# CTRL_MODULE_CORE register map
Vendor: Texas Instruments
Registers are 32-bit, access per field, reset 0x0 unless marked. A register's access mark holds for its fields unless they carry their own. Offsets are as the file gives them; [hi:lo] are bit positions; {n}, {i} and the like mark numbered series.

## CTRL_MODULE_CORE (part 4 of 5)
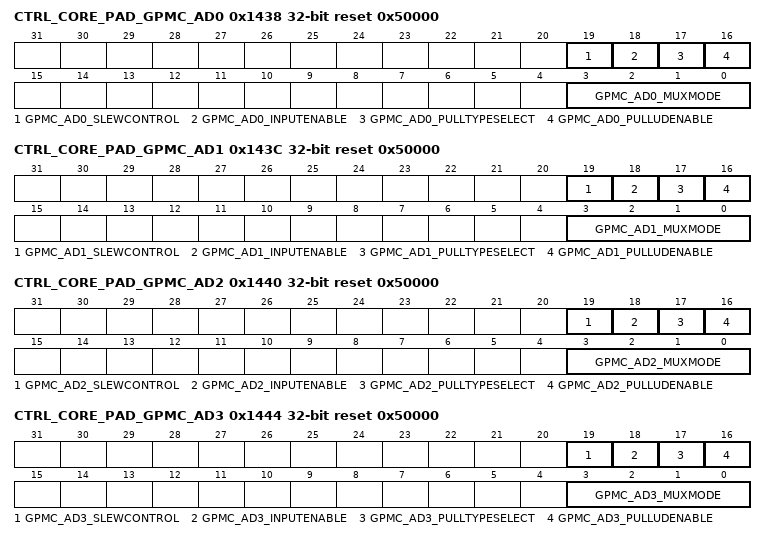
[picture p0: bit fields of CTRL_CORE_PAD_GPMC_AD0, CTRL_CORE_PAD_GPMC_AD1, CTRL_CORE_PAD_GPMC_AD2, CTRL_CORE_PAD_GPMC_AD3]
0x1438 CTRL_CORE_PAD_GPMC_AD0 reset 0x50000
  [19] GPMC_AD0_SLEWCONTROL rw
    0=Fast_slew_is_selected; 1=Slow_slew_is_selected
  [18] GPMC_AD0_INPUTENABLE rw
    0=Receive_mode_is_disabled; 1=Receive_mode_is_enabled
  [17] GPMC_AD0_PULLTYPESELECT rw
    0=Pull_Down_is_selected; 1=Pull_Up_is_selected
  [16] GPMC_AD0_PULLUDENABLE rw
    0=Enables_weak_Pull_Up/Down; 1=Disables_weak_Pull_Up/Down
  [3:0] GPMC_AD0_MUXMODE rw
    0=GPMC_AD0; 1=RGMII1_RXD2; 14=GPIO1_14; 15=SYSBOOT0
0x143C CTRL_CORE_PAD_GPMC_AD1 reset 0x50000
  [19] GPMC_AD1_SLEWCONTROL rw
    0=Fast_slew_is_selected; 1=Slow_slew_is_selected
  [18] GPMC_AD1_INPUTENABLE rw
    0=Receive_mode_is_disabled; 1=Receive_mode_is_enabled
  [17] GPMC_AD1_PULLTYPESELECT rw
    0=Pull_Down_is_selected; 1=Pull_Up_is_selected
  [16] GPMC_AD1_PULLUDENABLE rw
    0=Enables_weak_Pull_Up/Down; 1=Disables_weak_Pull_Up/Down
  [3:0] GPMC_AD1_MUXMODE rw
    0=GPMC_AD1; 1=RGMII1_RXD1; 14=GPIO1_15; 15=SYSBOOT1
0x1440 CTRL_CORE_PAD_GPMC_AD2 reset 0x50000
  [19] GPMC_AD2_SLEWCONTROL rw
    0=Fast_slew_is_selected; 1=Slow_slew_is_selected
  [18] GPMC_AD2_INPUTENABLE rw
    0=Receive_mode_is_disabled; 1=Receive_mode_is_enabled
  [17] GPMC_AD2_PULLTYPESELECT rw
    0=Pull_Down_is_selected; 1=Pull_Up_is_selected
  [16] GPMC_AD2_PULLUDENABLE rw
    0=Enables_weak_Pull_Up/Down; 1=Disables_weak_Pull_Up/Down
  [3:0] GPMC_AD2_MUXMODE rw
    0=GPMC_AD2; 1=RGMII1_RXD0; 14=GPIO1_16; 15=SYSBOOT2
0x1444 CTRL_CORE_PAD_GPMC_AD3 reset 0x50000
  [19] GPMC_AD3_SLEWCONTROL rw
    0=Fast_slew_is_selected; 1=Slow_slew_is_selected
  [18] GPMC_AD3_INPUTENABLE rw
    0=Receive_mode_is_disabled; 1=Receive_mode_is_enabled
  [17] GPMC_AD3_PULLTYPESELECT rw
    0=Pull_Down_is_selected; 1=Pull_Up_is_selected
  [16] GPMC_AD3_PULLUDENABLE rw
    0=Enables_weak_Pull_Up/Down; 1=Disables_weak_Pull_Up/Down
  [3:0] GPMC_AD3_MUXMODE rw
    0=GPMC_AD3; 1=QSPI1_RTCLK; 14=GPIO1_17; 15=SYSBOOT3
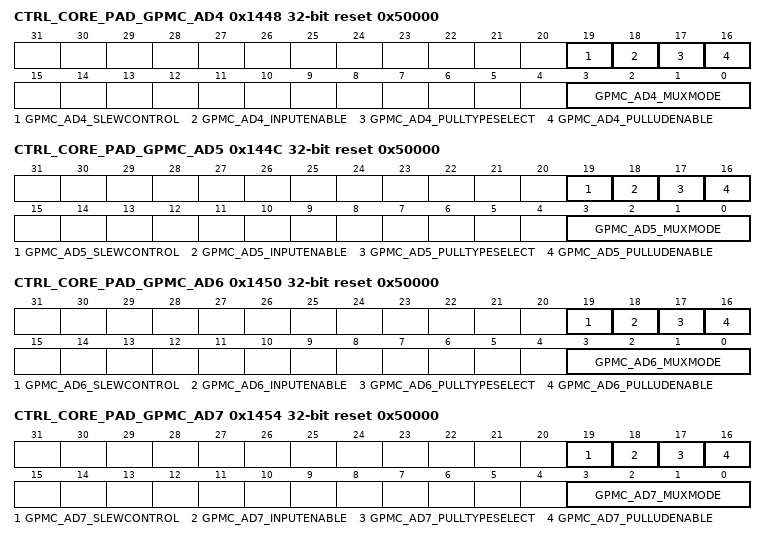
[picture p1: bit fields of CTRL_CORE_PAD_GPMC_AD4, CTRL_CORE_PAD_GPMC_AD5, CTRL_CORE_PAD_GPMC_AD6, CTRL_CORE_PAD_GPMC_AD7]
0x1448 CTRL_CORE_PAD_GPMC_AD4 reset 0x50000
  [19] GPMC_AD4_SLEWCONTROL rw
    0=Fast_slew_is_selected; 1=Slow_slew_is_selected
  [18] GPMC_AD4_INPUTENABLE rw
    0=Receive_mode_is_disabled; 1=Receive_mode_is_enabled
  [17] GPMC_AD4_PULLTYPESELECT rw
    0=Pull_Down_is_selected; 1=Pull_Up_is_selected
  [16] GPMC_AD4_PULLUDENABLE rw
    0=Enables_weak_Pull_Up/Down; 1=Disables_weak_Pull_Up/Down
  [3:0] GPMC_AD4_MUXMODE rw
    0=GPMC_AD4; 1=CAM_STROBE; 14=GPIO1_18; 15=SYSBOOT4
0x144C CTRL_CORE_PAD_GPMC_AD5 reset 0x50000
  [19] GPMC_AD5_SLEWCONTROL rw
    0=Fast_slew_is_selected; 1=Slow_slew_is_selected
  [18] GPMC_AD5_INPUTENABLE rw
    0=Receive_mode_is_disabled; 1=Receive_mode_is_enabled
  [17] GPMC_AD5_PULLTYPESELECT rw
    0=Pull_Down_is_selected; 1=Pull_Up_is_selected
  [16] GPMC_AD5_PULLUDENABLE rw
    0=Enables_weak_Pull_Up/Down; 1=Disables_weak_Pull_Up/Down
  [3:0] GPMC_AD5_MUXMODE rw
    0=GPMC_AD5; 2=UART2_TXD; 3=TIMER6; 4=SPI3_D1; 14=GPIO1_19; 15=SYSBOOT5
0x1450 CTRL_CORE_PAD_GPMC_AD6 reset 0x50000
  [19] GPMC_AD6_SLEWCONTROL rw
    0=Fast_slew_is_selected; 1=Slow_slew_is_selected
  [18] GPMC_AD6_INPUTENABLE rw
    0=Receive_mode_is_disabled; 1=Receive_mode_is_enabled
  [17] GPMC_AD6_PULLTYPESELECT rw
    0=Pull_Down_is_selected; 1=Pull_Up_is_selected
  [16] GPMC_AD6_PULLUDENABLE rw
    0=Enables_weak_Pull_Up/Down; 1=Disables_weak_Pull_Up/Down
  [3:0] GPMC_AD6_MUXMODE rw
    0=GPMC_AD6; 2=UART2_RXD; 3=TIMER5; 4=SPI3_D0; 14=GPIO1_20; 15=SYSBOOT6
0x1454 CTRL_CORE_PAD_GPMC_AD7 reset 0x50000
  [19] GPMC_AD7_SLEWCONTROL rw
    0=Fast_slew_is_selected; 1=Slow_slew_is_selected
  [18] GPMC_AD7_INPUTENABLE rw
    0=Receive_mode_is_disabled; 1=Receive_mode_is_enabled
  [17] GPMC_AD7_PULLTYPESELECT rw
    0=Pull_Down_is_selected; 1=Pull_Up_is_selected
  [16] GPMC_AD7_PULLUDENABLE rw
    0=Enables_weak_Pull_Up/Down; 1=Disables_weak_Pull_Up/Down
  [3:0] GPMC_AD7_MUXMODE rw
    0=GPMC_AD7; 1=CAM_SHUTTER; 3=TIMER4; 4=SPI3_SCLK; 14=GPIO1_21; 15=DRIVER_OFF
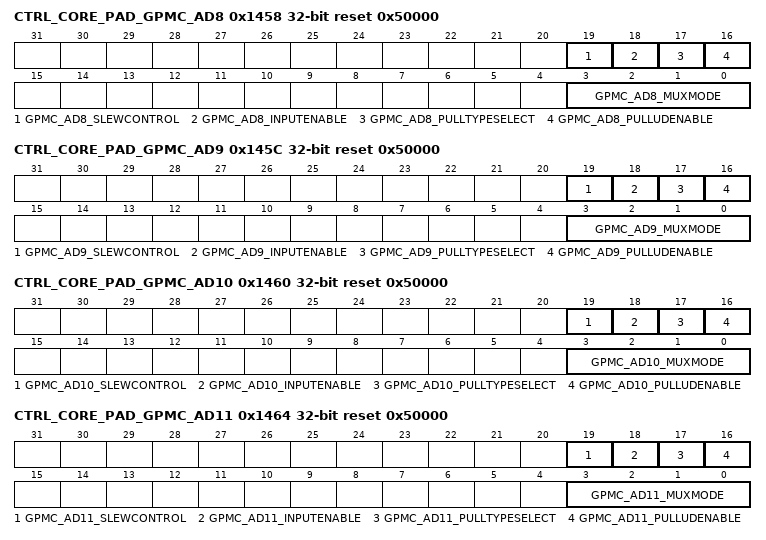
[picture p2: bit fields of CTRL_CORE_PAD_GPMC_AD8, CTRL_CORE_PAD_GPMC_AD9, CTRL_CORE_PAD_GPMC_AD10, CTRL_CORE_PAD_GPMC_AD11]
0x1458 CTRL_CORE_PAD_GPMC_AD8 reset 0x50000
  [19] GPMC_AD8_SLEWCONTROL rw
    0=Fast_slew_is_selected; 1=Slow_slew_is_selected
  [18] GPMC_AD8_INPUTENABLE rw
    0=Receive_mode_is_disabled; 1=Receive_mode_is_enabled
  [17] GPMC_AD8_PULLTYPESELECT rw
    0=Pull_Down_is_selected; 1=Pull_Up_is_selected
  [16] GPMC_AD8_PULLUDENABLE rw
    0=Enables_weak_Pull_Up/Down; 1=Disables_weak_Pull_Up/Down
  [3:0] GPMC_AD8_MUXMODE rw
    0=GPMC_AD8; 3=TIMER7; 4=SPI3_CS0; 14=GPIO1_22; 15=SYSBOOT8
0x145C CTRL_CORE_PAD_GPMC_AD9 reset 0x50000
  [19] GPMC_AD9_SLEWCONTROL rw
    0=Fast_slew_is_selected; 1=Slow_slew_is_selected
  [18] GPMC_AD9_INPUTENABLE rw
    0=Receive_mode_is_disabled; 1=Receive_mode_is_enabled
  [17] GPMC_AD9_PULLTYPESELECT rw
    0=Pull_Down_is_selected; 1=Pull_Up_is_selected
  [16] GPMC_AD9_PULLUDENABLE rw
    0=Enables_weak_Pull_Up/Down; 1=Disables_weak_Pull_Up/Down
  [3:0] GPMC_AD9_MUXMODE rw
    0=GPMC_AD9; 3=ECAP1_IN_PWM1_OUT; 4=SPI3_CS1; 14=GPIO1_23; 15=SYSBOOT9
0x1460 CTRL_CORE_PAD_GPMC_AD10 reset 0x50000
  [19] GPMC_AD10_SLEWCONTROL rw
    0=Fast_slew_is_selected; 1=Slow_slew_is_selected
  [18] GPMC_AD10_INPUTENABLE rw
    0=Receive_mode_is_disabled; 1=Receive_mode_is_enabled
  [17] GPMC_AD10_PULLTYPESELECT rw
    0=Pull_Down_is_selected; 1=Pull_Up_is_selected
  [16] GPMC_AD10_PULLUDENABLE rw
    0=Enables_weak_Pull_Up/Down; 1=Disables_weak_Pull_Up/Down
  [3:0] GPMC_AD10_MUXMODE rw
    0=GPMC_AD10; 3=TIMER2; 14=GPIO1_24; 15=SYSBOOT10
0x1464 CTRL_CORE_PAD_GPMC_AD11 reset 0x50000
  [19] GPMC_AD11_SLEWCONTROL rw
    0=Fast_slew_is_selected; 1=Slow_slew_is_selected
  [18] GPMC_AD11_INPUTENABLE rw
    0=Receive_mode_is_disabled; 1=Receive_mode_is_enabled
  [17] GPMC_AD11_PULLTYPESELECT rw
    0=Pull_Down_is_selected; 1=Pull_Up_is_selected
  [16] GPMC_AD11_PULLUDENABLE rw
    0=Enables_weak_Pull_Up/Down; 1=Disables_weak_Pull_Up/Down
  [3:0] GPMC_AD11_MUXMODE rw
    0=GPMC_AD11; 3=TIMER3; 14=GPIO1_25; 15=SYSBOOT11
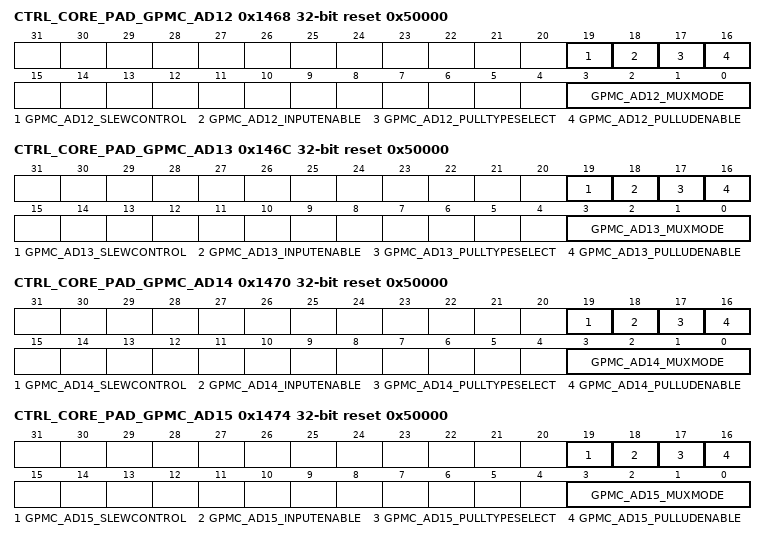
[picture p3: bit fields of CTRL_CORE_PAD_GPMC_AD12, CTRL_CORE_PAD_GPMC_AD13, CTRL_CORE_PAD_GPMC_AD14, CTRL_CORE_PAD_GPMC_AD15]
0x1468 CTRL_CORE_PAD_GPMC_AD12 reset 0x50000
  [19] GPMC_AD12_SLEWCONTROL rw
    0=Fast_slew_is_selected; 1=Slow_slew_is_selected
  [18] GPMC_AD12_INPUTENABLE rw
    0=Receive_mode_is_disabled; 1=Receive_mode_is_enabled
  [17] GPMC_AD12_PULLTYPESELECT rw
    0=Pull_Down_is_selected; 1=Pull_Up_is_selected
  [16] GPMC_AD12_PULLUDENABLE rw
    0=Enables_weak_Pull_Up/Down; 1=Disables_weak_Pull_Up/Down
  [3:0] GPMC_AD12_MUXMODE rw
    0=GPMC_AD12; 14=GPIO1_26; 15=SYSBOOT12
0x146C CTRL_CORE_PAD_GPMC_AD13 reset 0x50000
  [19] GPMC_AD13_SLEWCONTROL rw
    0=Fast_slew_is_selected; 1=Slow_slew_is_selected
  [18] GPMC_AD13_INPUTENABLE rw
    0=Receive_mode_is_disabled; 1=Receive_mode_is_enabled
  [17] GPMC_AD13_PULLTYPESELECT rw
    0=Pull_Down_is_selected; 1=Pull_Up_is_selected
  [16] GPMC_AD13_PULLUDENABLE rw
    0=Enables_weak_Pull_Up/Down; 1=Disables_weak_Pull_Up/Down
  [3:0] GPMC_AD13_MUXMODE rw
    0=GPMC_AD13; 1=RGMII1_RXC; 14=GPIO1_27; 15=SYSBOOT13
0x1470 CTRL_CORE_PAD_GPMC_AD14 reset 0x50000
  [19] GPMC_AD14_SLEWCONTROL rw
    0=Fast_slew_is_selected; 1=Slow_slew_is_selected
  [18] GPMC_AD14_INPUTENABLE rw
    0=Receive_mode_is_disabled; 1=Receive_mode_is_enabled
  [17] GPMC_AD14_PULLTYPESELECT rw
    0=Pull_Down_is_selected; 1=Pull_Up_is_selected
  [16] GPMC_AD14_PULLUDENABLE rw
    0=Enables_weak_Pull_Up/Down; 1=Disables_weak_Pull_Up/Down
  [3:0] GPMC_AD14_MUXMODE rw
    0=GPMC_AD14; 4=SPI2_CS1; 14=GPIO1_28; 15=SYSBOOT14
0x1474 CTRL_CORE_PAD_GPMC_AD15 reset 0x50000
  [19] GPMC_AD15_SLEWCONTROL rw
    0=Fast_slew_is_selected; 1=Slow_slew_is_selected
  [18] GPMC_AD15_INPUTENABLE rw
    0=Receive_mode_is_disabled; 1=Receive_mode_is_enabled
  [17] GPMC_AD15_PULLTYPESELECT rw
    0=Pull_Down_is_selected; 1=Pull_Up_is_selected
  [16] GPMC_AD15_PULLUDENABLE rw
    0=Enables_weak_Pull_Up/Down; 1=Disables_weak_Pull_Up/Down
  [3:0] GPMC_AD15_MUXMODE rw
    0=GPMC_AD15; 4=SPI2_CS0; 14=GPIO1_29; 15=SYSBOOT15
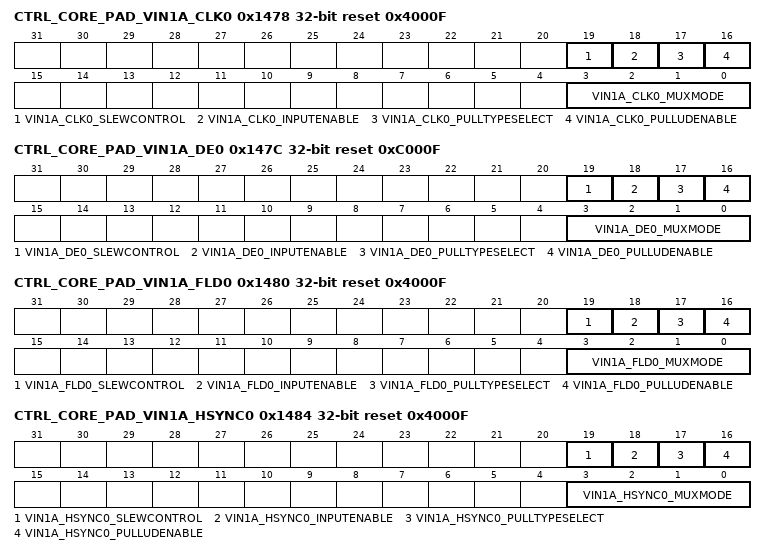
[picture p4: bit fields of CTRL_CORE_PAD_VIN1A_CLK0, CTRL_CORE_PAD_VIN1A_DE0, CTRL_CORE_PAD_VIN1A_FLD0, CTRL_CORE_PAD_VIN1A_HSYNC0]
0x1478 CTRL_CORE_PAD_VIN1A_CLK0 reset 0x4000F
  [19] VIN1A_CLK0_SLEWCONTROL rw
    0=Fast_slew_is_selected; 1=Slow_slew_is_selected
  [18] VIN1A_CLK0_INPUTENABLE rw
    0=Receive_mode_is_disabled; 1=Receive_mode_is_enabled
  [17] VIN1A_CLK0_PULLTYPESELECT rw
    0=Pull_Down_is_selected; 1=Pull_Up_is_selected
  [16] VIN1A_CLK0_PULLUDENABLE rw
    0=Enables_weak_Pull_Up/Down; 1=Disables_weak_Pull_Up/Down
  [3:0] VIN1A_CLK0_MUXMODE rw
    0=VIN1A_CLK0; 1=CPI_PCLK; 4=CLKOUT0; 14=GPIO1_30; 15=DRIVER_OFF
0x147C CTRL_CORE_PAD_VIN1A_DE0 reset 0xC000F
  [19] VIN1A_DE0_SLEWCONTROL rw
    0=Fast_slew_is_selected; 1=Slow_slew_is_selected
  [18] VIN1A_DE0_INPUTENABLE rw
    0=Receive_mode_is_disabled; 1=Receive_mode_is_enabled
  [17] VIN1A_DE0_PULLTYPESELECT rw
    0=Pull_Down_is_selected; 1=Pull_Up_is_selected
  [16] VIN1A_DE0_PULLUDENABLE rw
    0=Enables_weak_Pull_Up/Down; 1=Disables_weak_Pull_Up/Down
  [3:0] VIN1A_DE0_MUXMODE rw
    0=VIN1A_DE0; 1=CPI_HSYNC; 2=VIN1B_CLK1; 4=CLKOUT1; 14=GPIO1_31; 15=DRIVER_OFF
0x1480 CTRL_CORE_PAD_VIN1A_FLD0 reset 0x4000F
  [19] VIN1A_FLD0_SLEWCONTROL rw
    0=Fast_slew_is_selected; 1=Slow_slew_is_selected
  [18] VIN1A_FLD0_INPUTENABLE rw
    0=Receive_mode_is_disabled; 1=Receive_mode_is_enabled
  [17] VIN1A_FLD0_PULLTYPESELECT rw
    0=Pull_Down_is_selected; 1=Pull_Up_is_selected
  [16] VIN1A_FLD0_PULLUDENABLE rw
    0=Enables_weak_Pull_Up/Down; 1=Disables_weak_Pull_Up/Down
  [3:0] VIN1A_FLD0_MUXMODE rw
    0=VIN1A_FLD0; 1=CPI_VSYNC; 2=VIN2B_CLK1; 4=CLKOUT2; 14=GPIO2_0; 15=DRIVER_OFF
0x1484 CTRL_CORE_PAD_VIN1A_HSYNC0 reset 0x4000F
  [19] VIN1A_HSYNC0_SLEWCONTROL rw
    0=Fast_slew_is_selected; 1=Slow_slew_is_selected
  [18] VIN1A_HSYNC0_INPUTENABLE rw
    0=Receive_mode_is_disabled; 1=Receive_mode_is_enabled
  [17] VIN1A_HSYNC0_PULLTYPESELECT rw
    0=Pull_Down_is_selected; 1=Pull_Up_is_selected
  [16] VIN1A_HSYNC0_PULLUDENABLE rw
    0=Enables_weak_Pull_Up/Down; 1=Disables_weak_Pull_Up/Down
  [3:0] VIN1A_HSYNC0_MUXMODE rw
    0=VIN1A_HSYNC0; 1=CPI_DATA0; 2=VIN1A_DE0; 14=GPIO2_1; 15=DRIVER_OFF
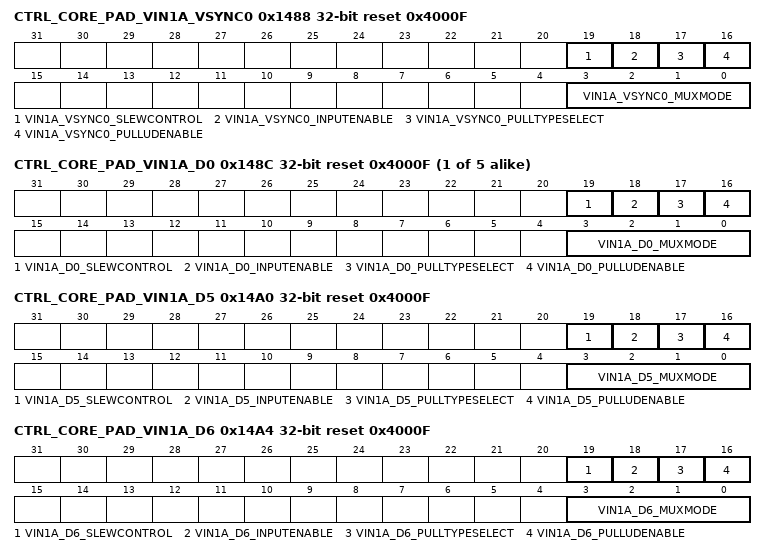
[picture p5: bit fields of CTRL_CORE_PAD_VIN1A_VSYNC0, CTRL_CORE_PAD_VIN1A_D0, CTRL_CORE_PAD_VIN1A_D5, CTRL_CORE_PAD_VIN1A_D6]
0x1488 CTRL_CORE_PAD_VIN1A_VSYNC0 reset 0x4000F
  [19] VIN1A_VSYNC0_SLEWCONTROL rw
    0=Fast_slew_is_selected; 1=Slow_slew_is_selected
  [18] VIN1A_VSYNC0_INPUTENABLE rw
    0=Receive_mode_is_disabled; 1=Receive_mode_is_enabled
  [17] VIN1A_VSYNC0_PULLTYPESELECT rw
    0=Pull_Down_is_selected; 1=Pull_Up_is_selected
  [16] VIN1A_VSYNC0_PULLUDENABLE rw
    0=Enables_weak_Pull_Up/Down; 1=Disables_weak_Pull_Up/Down
  [3:0] VIN1A_VSYNC0_MUXMODE rw
    0=VIN1A_VSYNC0; 1=CPI_DATA1; 14=GPIO2_2; 15=DRIVER_OFF
{0x148C+4i} CTRL_CORE_PAD_VIN1A_D{i} reset 0x4000F (i=0..4)
  [19] VIN1A_D{i}_SLEWCONTROL rw
    0=Fast_slew_is_selected; 1=Slow_slew_is_selected
  [18] VIN1A_D{i}_INPUTENABLE rw
    0=Receive_mode_is_disabled; 1=Receive_mode_is_enabled
  [17] VIN1A_D{i}_PULLTYPESELECT rw
    0=Pull_Down_is_selected; 1=Pull_Up_is_selected
  [16] VIN1A_D{i}_PULLUDENABLE rw
    0=Enables_weak_Pull_Up/Down; 1=Disables_weak_Pull_Up/Down
  [3:0] VIN1A_D{i}_MUXMODE rw
    0=VIN1A_D{i}; 1=CPI_DATA{i+2}; 14=GPIO2_{i+3}; 15=DRIVER_OFF
0x14A0 CTRL_CORE_PAD_VIN1A_D5 reset 0x4000F
  [19] VIN1A_D5_SLEWCONTROL rw
    0=Fast_slew_is_selected; 1=Slow_slew_is_selected
  [18] VIN1A_D5_INPUTENABLE rw
    0=Receive_mode_is_disabled; 1=Receive_mode_is_enabled
  [17] VIN1A_D5_PULLTYPESELECT rw
    0=Pull_Down_is_selected; 1=Pull_Up_is_selected
  [16] VIN1A_D5_PULLUDENABLE rw
    0=Enables_weak_Pull_Up/Down; 1=Disables_weak_Pull_Up/Down
  [3:0] VIN1A_D5_MUXMODE rw
    0=VIN1A_D5; 1=CPI_DATA7; 14=GPIO2_8; 15=DRIVER_OFF_SR1.0_XREF_CLK2_SR2.0 (Driver off (SR1.0 Only) / xref_clk2 (SR2.0 Only))
0x14A4 CTRL_CORE_PAD_VIN1A_D6 reset 0x4000F
  [19] VIN1A_D6_SLEWCONTROL rw
    0=Fast_slew_is_selected; 1=Slow_slew_is_selected
  [18] VIN1A_D6_INPUTENABLE rw
    0=Receive_mode_is_disabled; 1=Receive_mode_is_enabled
  [17] VIN1A_D6_PULLTYPESELECT rw
    0=Pull_Down_is_selected; 1=Pull_Up_is_selected
  [16] VIN1A_D6_PULLUDENABLE rw
    0=Enables_weak_Pull_Up/Down; 1=Disables_weak_Pull_Up/Down
  [3:0] VIN1A_D6_MUXMODE rw
    0=VIN1A_D6; 1=CPI_DATA8; 14=GPIO2_9; 15=DRIVER_OFF
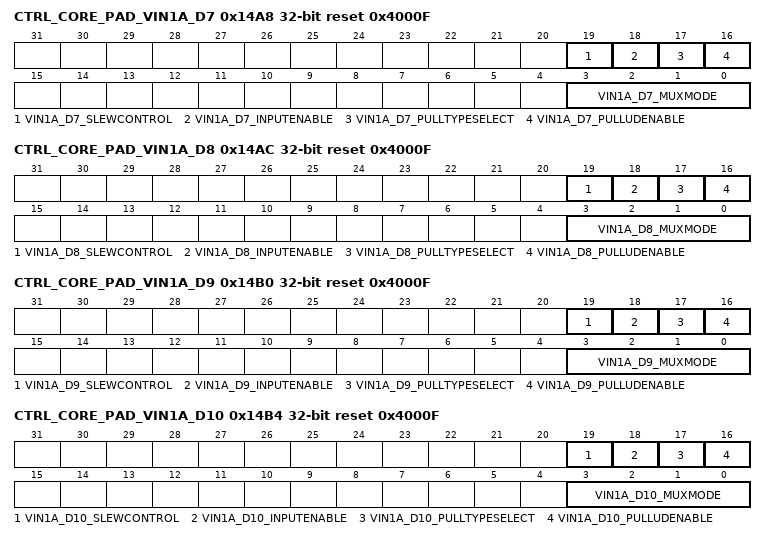
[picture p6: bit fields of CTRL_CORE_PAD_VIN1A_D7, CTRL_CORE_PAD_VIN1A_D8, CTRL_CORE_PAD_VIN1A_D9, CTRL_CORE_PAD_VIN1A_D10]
0x14A8 CTRL_CORE_PAD_VIN1A_D7 reset 0x4000F
  [19] VIN1A_D7_SLEWCONTROL rw
    0=Fast_slew_is_selected; 1=Slow_slew_is_selected
  [18] VIN1A_D7_INPUTENABLE rw
    0=Receive_mode_is_disabled; 1=Receive_mode_is_enabled
  [17] VIN1A_D7_PULLTYPESELECT rw
    0=Pull_Down_is_selected; 1=Pull_Up_is_selected
  [16] VIN1A_D7_PULLUDENABLE rw
    0=Enables_weak_Pull_Up/Down; 1=Disables_weak_Pull_Up/Down
  [3:0] VIN1A_D7_MUXMODE rw
    0=VIN1A_D7; 1=CPI_DATA9; 14=GPIO2_10; 15=DRIVER_OFF
0x14AC CTRL_CORE_PAD_VIN1A_D8 reset 0x4000F
  [19] VIN1A_D8_SLEWCONTROL rw
    0=Fast_slew_is_selected; 1=Slow_slew_is_selected
  [18] VIN1A_D8_INPUTENABLE rw
    0=Receive_mode_is_disabled; 1=Receive_mode_is_enabled
  [17] VIN1A_D8_PULLTYPESELECT rw
    0=Pull_Down_is_selected; 1=Pull_Up_is_selected
  [16] VIN1A_D8_PULLUDENABLE rw
    0=Enables_weak_Pull_Up/Down; 1=Disables_weak_Pull_Up/Down
  [3:0] VIN1A_D8_MUXMODE rw
    0=VIN1A_D8; 1=CPI_DATA10; 2=VIN1B_D0; 3=GPMC_A8; 7=SYS_NIRQ2; 14=GPIO2_11; 15=DRIVER_OFF
0x14B0 CTRL_CORE_PAD_VIN1A_D9 reset 0x4000F
  [19] VIN1A_D9_SLEWCONTROL rw
    0=Fast_slew_is_selected; 1=Slow_slew_is_selected
  [18] VIN1A_D9_INPUTENABLE rw
    0=Receive_mode_is_disabled; 1=Receive_mode_is_enabled
  [17] VIN1A_D9_PULLTYPESELECT rw
    0=Pull_Down_is_selected; 1=Pull_Up_is_selected
  [16] VIN1A_D9_PULLUDENABLE rw
    0=Enables_weak_Pull_Up/Down; 1=Disables_weak_Pull_Up/Down
  [3:0] VIN1A_D9_MUXMODE rw
    0=VIN1A_D9; 1=CPI_DATA11; 2=VIN1B_D1; 3=GPMC_A9; 7=SYS_NIRQ1; 14=GPIO2_12; 15=DRIVER_OFF
0x14B4 CTRL_CORE_PAD_VIN1A_D10 reset 0x4000F
  [19] VIN1A_D10_SLEWCONTROL rw
    0=Fast_slew_is_selected; 1=Slow_slew_is_selected
  [18] VIN1A_D10_INPUTENABLE rw
    0=Receive_mode_is_disabled; 1=Receive_mode_is_enabled
  [17] VIN1A_D10_PULLTYPESELECT rw
    0=Pull_Down_is_selected; 1=Pull_Up_is_selected
  [16] VIN1A_D10_PULLUDENABLE rw
    0=Enables_weak_Pull_Up/Down; 1=Disables_weak_Pull_Up/Down
  [3:0] VIN1A_D10_MUXMODE rw
    0=VIN1A_D10; 1=CPI_DATA12; 2=VIN1B_D2; 3=GPMC_A10; 7=SYS_NIRQ2; 14=GPIO2_13; 15=DRIVER_OFF
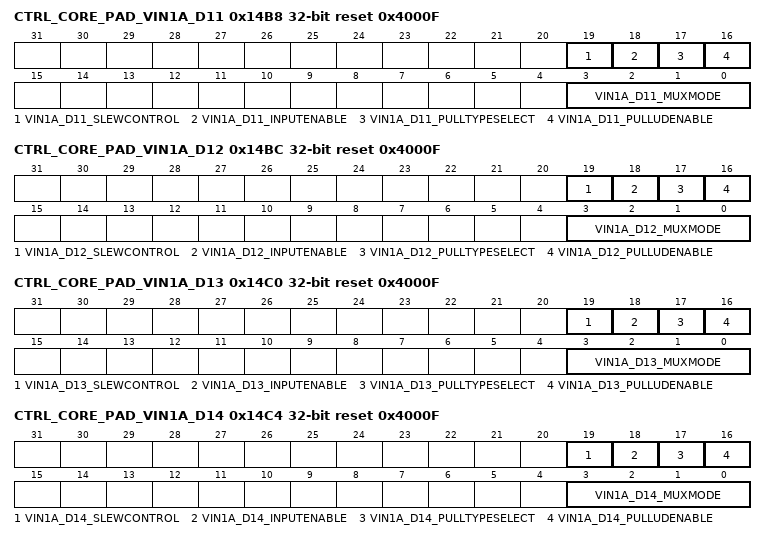
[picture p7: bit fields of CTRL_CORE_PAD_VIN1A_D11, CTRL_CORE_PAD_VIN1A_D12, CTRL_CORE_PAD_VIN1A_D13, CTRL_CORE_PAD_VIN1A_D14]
0x14B8 CTRL_CORE_PAD_VIN1A_D11 reset 0x4000F
  [19] VIN1A_D11_SLEWCONTROL rw
    0=Fast_slew_is_selected; 1=Slow_slew_is_selected
  [18] VIN1A_D11_INPUTENABLE rw
    0=Receive_mode_is_disabled; 1=Receive_mode_is_enabled
  [17] VIN1A_D11_PULLTYPESELECT rw
    0=Pull_Down_is_selected; 1=Pull_Up_is_selected
  [16] VIN1A_D11_PULLUDENABLE rw
    0=Enables_weak_Pull_Up/Down; 1=Disables_weak_Pull_Up/Down
  [3:0] VIN1A_D11_MUXMODE rw
    0=VIN1A_D11; 1=CPI_DATA13; 2=VIN1B_D3; 3=GPMC_A11; 7=SYS_NIRQ1; 14=GPIO2_14; 15=DRIVER_OFF
0x14BC CTRL_CORE_PAD_VIN1A_D12 reset 0x4000F
  [19] VIN1A_D12_SLEWCONTROL rw
    0=Fast_slew_is_selected; 1=Slow_slew_is_selected
  [18] VIN1A_D12_INPUTENABLE rw
    0=Receive_mode_is_disabled; 1=Receive_mode_is_enabled
  [17] VIN1A_D12_PULLTYPESELECT rw
    0=Pull_Down_is_selected; 1=Pull_Up_is_selected
  [16] VIN1A_D12_PULLUDENABLE rw
    0=Enables_weak_Pull_Up/Down; 1=Disables_weak_Pull_Up/Down
  [3:0] VIN1A_D12_MUXMODE rw
    0=VIN1A_D12; 1=CPI_DATA14; 2=VIN1B_D4; 3=GPMC_A12; 6=DMA_EVT1; 14=GPIO2_15; 15=DRIVER_OFF
0x14C0 CTRL_CORE_PAD_VIN1A_D13 reset 0x4000F
  [19] VIN1A_D13_SLEWCONTROL rw
    0=Fast_slew_is_selected; 1=Slow_slew_is_selected
  [18] VIN1A_D13_INPUTENABLE rw
    0=Receive_mode_is_disabled; 1=Receive_mode_is_enabled
  [17] VIN1A_D13_PULLTYPESELECT rw
    0=Pull_Down_is_selected; 1=Pull_Up_is_selected
  [16] VIN1A_D13_PULLUDENABLE rw
    0=Enables_weak_Pull_Up/Down; 1=Disables_weak_Pull_Up/Down
  [3:0] VIN1A_D13_MUXMODE rw
    0=VIN1A_D13; 1=CPI_WEN; 2=VIN1B_D5; 3=GPMC_A13; 6=DMA_EVT2; 14=GPIO2_16; 15=DRIVER_OFF
0x14C4 CTRL_CORE_PAD_VIN1A_D14 reset 0x4000F
  [19] VIN1A_D14_SLEWCONTROL rw
    0=Fast_slew_is_selected; 1=Slow_slew_is_selected
  [18] VIN1A_D14_INPUTENABLE rw
    0=Receive_mode_is_disabled; 1=Receive_mode_is_enabled
  [17] VIN1A_D14_PULLTYPESELECT rw
    0=Pull_Down_is_selected; 1=Pull_Up_is_selected
  [16] VIN1A_D14_PULLUDENABLE rw
    0=Enables_weak_Pull_Up/Down; 1=Disables_weak_Pull_Up/Down
  [3:0] VIN1A_D14_MUXMODE rw
    0=VIN1A_D14; 1=CPI_FID; 2=VIN1B_D6; 3=GPMC_A14; 14=GPIO2_17; 15=DRIVER_OFF
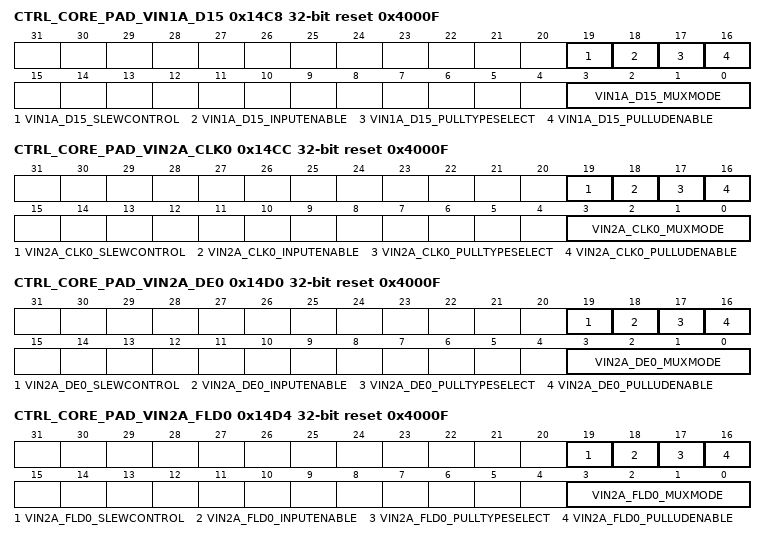
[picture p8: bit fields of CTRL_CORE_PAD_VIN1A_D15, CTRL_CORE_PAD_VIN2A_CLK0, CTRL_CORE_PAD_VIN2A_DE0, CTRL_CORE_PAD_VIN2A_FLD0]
0x14C8 CTRL_CORE_PAD_VIN1A_D15 reset 0x4000F
  [19] VIN1A_D15_SLEWCONTROL rw
    0=Fast_slew_is_selected; 1=Slow_slew_is_selected
  [18] VIN1A_D15_INPUTENABLE rw
    0=Receive_mode_is_disabled; 1=Receive_mode_is_enabled
  [17] VIN1A_D15_PULLTYPESELECT rw
    0=Pull_Down_is_selected; 1=Pull_Up_is_selected
  [16] VIN1A_D15_PULLUDENABLE rw
    0=Enables_weak_Pull_Up/Down; 1=Disables_weak_Pull_Up/Down
  [3:0] VIN1A_D15_MUXMODE rw
    0=VIN1A_D15; 1=CPI_DATA15; 2=VIN1B_D7; 3=GPMC_A15; 14=GPIO2_18; 15=DRIVER_OFF
0x14CC CTRL_CORE_PAD_VIN2A_CLK0 reset 0x4000F
  [19] VIN2A_CLK0_SLEWCONTROL rw
    0=Fast_slew_is_selected; 1=Slow_slew_is_selected
  [18] VIN2A_CLK0_INPUTENABLE rw
    0=Receive_mode_is_disabled; 1=Receive_mode_is_enabled
  [17] VIN2A_CLK0_PULLTYPESELECT rw
    0=Pull_Down_is_selected; 1=Pull_Up_is_selected
  [16] VIN2A_CLK0_PULLUDENABLE rw
    0=Enables_weak_Pull_Up/Down; 1=Disables_weak_Pull_Up/Down
  [3:0] VIN2A_CLK0_MUXMODE rw
    0=VIN2A_CLK0; 14=GPIO2_19; 15=DRIVER_OFF
0x14D0 CTRL_CORE_PAD_VIN2A_DE0 reset 0x4000F
  [19] VIN2A_DE0_SLEWCONTROL rw
    0=Fast_slew_is_selected; 1=Slow_slew_is_selected
  [18] VIN2A_DE0_INPUTENABLE rw
    0=Receive_mode_is_disabled; 1=Receive_mode_is_enabled
  [17] VIN2A_DE0_PULLTYPESELECT rw
    0=Pull_Down_is_selected; 1=Pull_Up_is_selected
  [16] VIN2A_DE0_PULLUDENABLE rw
    0=Enables_weak_Pull_Up/Down; 1=Disables_weak_Pull_Up/Down
  [3:0] VIN2A_DE0_MUXMODE rw
    0=VIN2A_DE0; 1=CAM_STROBE; 2=VIN2B_HSYNC1; 5=VIN2B_DE1; 14=GPIO4_21; 15=DRIVER_OFF
0x14D4 CTRL_CORE_PAD_VIN2A_FLD0 reset 0x4000F
  [19] VIN2A_FLD0_SLEWCONTROL rw
    0=Fast_slew_is_selected; 1=Slow_slew_is_selected
  [18] VIN2A_FLD0_INPUTENABLE rw
    0=Receive_mode_is_disabled; 1=Receive_mode_is_enabled
  [17] VIN2A_FLD0_PULLTYPESELECT rw
    0=Pull_Down_is_selected; 1=Pull_Up_is_selected
  [16] VIN2A_FLD0_PULLUDENABLE rw
    0=Enables_weak_Pull_Up/Down; 1=Disables_weak_Pull_Up/Down
  [3:0] VIN2A_FLD0_MUXMODE rw
    0=VIN2A_FLD0; 1=CAM_SHUTTER; 2=VIN2B_VSYNC1; 14=GPIO4_22; 15=DRIVER_OFF
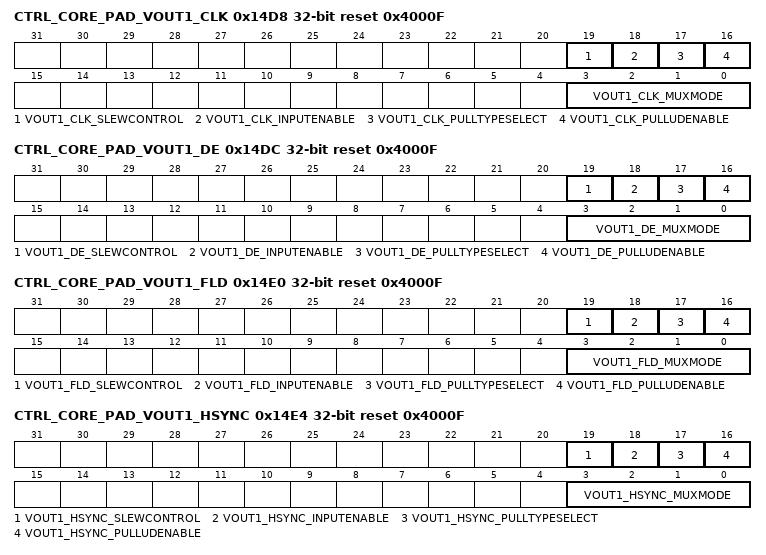
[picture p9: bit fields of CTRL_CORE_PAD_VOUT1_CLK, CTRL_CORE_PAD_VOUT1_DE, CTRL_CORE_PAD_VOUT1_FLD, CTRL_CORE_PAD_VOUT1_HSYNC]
0x14D8 CTRL_CORE_PAD_VOUT1_CLK reset 0x4000F
  [19] VOUT1_CLK_SLEWCONTROL rw
    0=Fast_slew_is_selected; 1=Slow_slew_is_selected
  [18] VOUT1_CLK_INPUTENABLE rw
    0=Receive_mode_is_disabled; 1=Receive_mode_is_enabled
  [17] VOUT1_CLK_PULLTYPESELECT rw
    0=Pull_Down_is_selected; 1=Pull_Up_is_selected
  [16] VOUT1_CLK_PULLUDENABLE rw
    0=Enables_weak_Pull_Up/Down; 1=Disables_weak_Pull_Up/Down
  [3:0] VOUT1_CLK_MUXMODE rw
    0=VOUT1_CLK; 2=VIN1A_D12; 4=CLKOUT0; 9=VIN2A_CLK0; 14=GPIO2_20; 15=DRIVER_OFF
0x14DC CTRL_CORE_PAD_VOUT1_DE reset 0x4000F
  [19] VOUT1_DE_SLEWCONTROL rw
    0=Fast_slew_is_selected; 1=Slow_slew_is_selected
  [18] VOUT1_DE_INPUTENABLE rw
    0=Receive_mode_is_disabled; 1=Receive_mode_is_enabled
  [17] VOUT1_DE_PULLTYPESELECT rw
    0=Pull_Down_is_selected; 1=Pull_Up_is_selected
  [16] VOUT1_DE_PULLUDENABLE rw
    0=Enables_weak_Pull_Up/Down; 1=Disables_weak_Pull_Up/Down
  [3:0] VOUT1_DE_MUXMODE rw
    0=VOUT1_DE; 1=MCASP1_ACLKX; 2=VIN1A_D13; 4=CLKOUT1; 14=GPIO2_21; 15=DRIVER_OFF
0x14E0 CTRL_CORE_PAD_VOUT1_FLD reset 0x4000F
  [19] VOUT1_FLD_SLEWCONTROL rw
    0=Fast_slew_is_selected; 1=Slow_slew_is_selected
  [18] VOUT1_FLD_INPUTENABLE rw
    0=Receive_mode_is_disabled; 1=Receive_mode_is_enabled
  [17] VOUT1_FLD_PULLTYPESELECT rw
    0=Pull_Down_is_selected; 1=Pull_Up_is_selected
  [16] VOUT1_FLD_PULLUDENABLE rw
    0=Enables_weak_Pull_Up/Down; 1=Disables_weak_Pull_Up/Down
  [3:0] VOUT1_FLD_MUXMODE rw
    0=VOUT1_FLD; 1=MCASP1_FSX; 2=VIN1A_D14; 4=CLKOUT2; 14=GPIO2_22; 15=DRIVER_OFF
0x14E4 CTRL_CORE_PAD_VOUT1_HSYNC reset 0x4000F
  [19] VOUT1_HSYNC_SLEWCONTROL rw
    0=Fast_slew_is_selected; 1=Slow_slew_is_selected
  [18] VOUT1_HSYNC_INPUTENABLE rw
    0=Receive_mode_is_disabled; 1=Receive_mode_is_enabled
  [17] VOUT1_HSYNC_PULLTYPESELECT rw
    0=Pull_Down_is_selected; 1=Pull_Up_is_selected
  [16] VOUT1_HSYNC_PULLUDENABLE rw
    0=Enables_weak_Pull_Up/Down; 1=Disables_weak_Pull_Up/Down
  [3:0] VOUT1_HSYNC_MUXMODE rw
    0=VOUT1_HSYNC; 1=MCASP1_ACLKR; 2=VIN1A_D15; 9=VIN2A_DE0; 14=GPIO2_23; 15=DRIVER_OFF
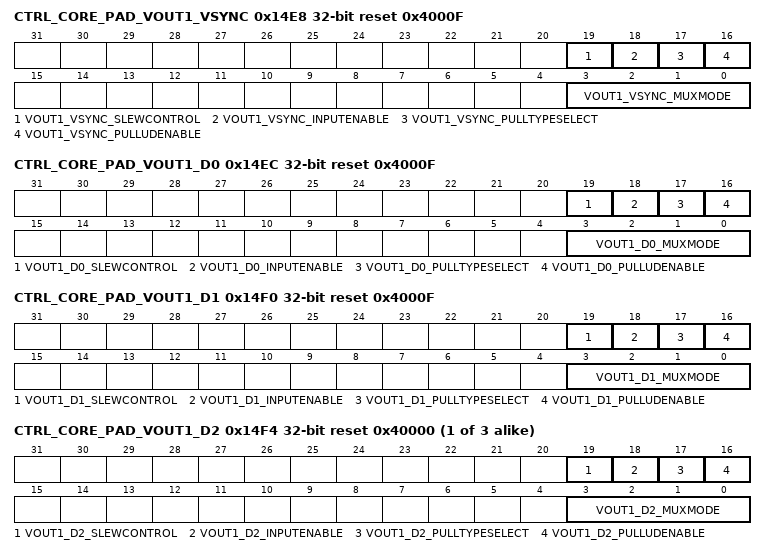
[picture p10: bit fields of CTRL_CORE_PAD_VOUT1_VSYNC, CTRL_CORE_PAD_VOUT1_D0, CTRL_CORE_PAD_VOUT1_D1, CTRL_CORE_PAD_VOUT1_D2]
0x14E8 CTRL_CORE_PAD_VOUT1_VSYNC reset 0x4000F
  [19] VOUT1_VSYNC_SLEWCONTROL rw
    0=Fast_slew_is_selected; 1=Slow_slew_is_selected
  [18] VOUT1_VSYNC_INPUTENABLE rw
    0=Receive_mode_is_disabled; 1=Receive_mode_is_enabled
  [17] VOUT1_VSYNC_PULLTYPESELECT rw
    0=Pull_Down_is_selected; 1=Pull_Up_is_selected
  [16] VOUT1_VSYNC_PULLUDENABLE rw
    0=Enables_weak_Pull_Up/Down; 1=Disables_weak_Pull_Up/Down
  [3:0] VOUT1_VSYNC_MUXMODE rw
    0=VOUT1_VSYNC; 1=MCASP1_FSR; 2=VIN1A_D16; 9=VIN2A_FLD0; 14=GPIO2_24; 15=DRIVER_OFF
0x14EC CTRL_CORE_PAD_VOUT1_D0 reset 0x4000F
  [19] VOUT1_D0_SLEWCONTROL rw
    0=Fast_slew_is_selected; 1=Slow_slew_is_selected
  [18] VOUT1_D0_INPUTENABLE rw
    0=Receive_mode_is_disabled; 1=Receive_mode_is_enabled
  [17] VOUT1_D0_PULLTYPESELECT rw
    0=Pull_Down_is_selected; 1=Pull_Up_is_selected
  [16] VOUT1_D0_PULLUDENABLE rw
    0=Enables_weak_Pull_Up/Down; 1=Disables_weak_Pull_Up/Down
  [3:0] VOUT1_D0_MUXMODE rw
    0=VOUT1_D0; 1=MCASP1_AXR0; 5=MMC_CLK; 14=GPIO2_25; 15=DRIVER_OFF
0x14F0 CTRL_CORE_PAD_VOUT1_D1 reset 0x4000F
  [19] VOUT1_D1_SLEWCONTROL rw
    0=Fast_slew_is_selected; 1=Slow_slew_is_selected
  [18] VOUT1_D1_INPUTENABLE rw
    0=Receive_mode_is_disabled; 1=Receive_mode_is_enabled
  [17] VOUT1_D1_PULLTYPESELECT rw
    0=Pull_Down_is_selected; 1=Pull_Up_is_selected
  [16] VOUT1_D1_PULLUDENABLE rw
    0=Enables_weak_Pull_Up/Down; 1=Disables_weak_Pull_Up/Down
  [3:0] VOUT1_D1_MUXMODE rw
    0=VOUT1_D1; 1=MCASP1_AXR1; 5=MMC_CMD; 14=GPIO2_26; 15=DRIVER_OFF
{0x14EC+4i} CTRL_CORE_PAD_VOUT1_D{i} reset 0x40000 (reset mask 0xFFFFFFF0) (i=2..4)
  [19] VOUT1_D{i}_SLEWCONTROL rw
    0=Fast_slew_is_selected; 1=Slow_slew_is_selected
  [18] VOUT1_D{i}_INPUTENABLE rw
    0=Receive_mode_is_disabled; 1=Receive_mode_is_enabled
  [17] VOUT1_D{i}_PULLTYPESELECT rw
    0=Pull_Down_is_selected; 1=Pull_Up_is_selected
  [16] VOUT1_D{i}_PULLUDENABLE rw
    0=Enables_weak_Pull_Up/Down; 1=Disables_weak_Pull_Up/Down
  [3:0] VOUT1_D{i}_MUXMODE rw
    0=VOUT1_D{i}; 1=MCASP1_AXR{i}; 4=MCASP1_AXR{i+6}; 5=MMC_DAT{i-2}; 14=GPIO2_{i+25}; 15=DRIVER_OFF
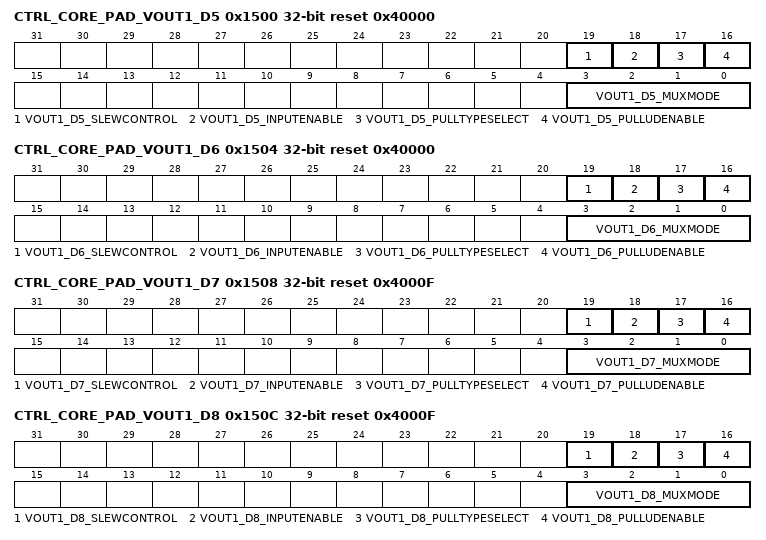
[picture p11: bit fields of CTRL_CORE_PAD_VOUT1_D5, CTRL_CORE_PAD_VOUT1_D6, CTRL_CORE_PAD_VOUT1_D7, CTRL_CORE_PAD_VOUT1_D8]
0x1500 CTRL_CORE_PAD_VOUT1_D5 reset 0x40000 (reset mask 0xFFFFFFF0)
  [19] VOUT1_D5_SLEWCONTROL rw
    0=Fast_slew_is_selected; 1=Slow_slew_is_selected
  [18] VOUT1_D5_INPUTENABLE rw
    0=Receive_mode_is_disabled; 1=Receive_mode_is_enabled
  [17] VOUT1_D5_PULLTYPESELECT rw
    0=Pull_Down_is_selected; 1=Pull_Up_is_selected
  [16] VOUT1_D5_PULLUDENABLE rw
    0=Enables_weak_Pull_Up/Down; 1=Disables_weak_Pull_Up/Down
  [3:0] VOUT1_D5_MUXMODE rw
    0=VOUT1_D5; 1=MCASP1_AXR5; 4=MCASP1_AXR11; 5=MMC_DAT3; 9=VIN2A_CLK0; 14=GPIO2_30; 15=DRIVER_OFF
0x1504 CTRL_CORE_PAD_VOUT1_D6 reset 0x40000 (reset mask 0xFFFFFFF0)
  [19] VOUT1_D6_SLEWCONTROL rw
    0=Fast_slew_is_selected; 1=Slow_slew_is_selected
  [18] VOUT1_D6_INPUTENABLE rw
    0=Receive_mode_is_disabled; 1=Receive_mode_is_enabled
  [17] VOUT1_D6_PULLTYPESELECT rw
    0=Pull_Down_is_selected; 1=Pull_Up_is_selected
  [16] VOUT1_D6_PULLUDENABLE rw
    0=Enables_weak_Pull_Up/Down; 1=Disables_weak_Pull_Up/Down
  [3:0] VOUT1_D6_MUXMODE rw
    0=VOUT1_D6; 1=MCASP1_AXR6; 4=MCASP1_AXR12; 5=ESM_ERROR; 6=EMU2; 9=VIN2A_DE0; 14=GPIO2_31; 15=DRIVER_OFF
0x1508 CTRL_CORE_PAD_VOUT1_D7 reset 0x4000F
  [19] VOUT1_D7_SLEWCONTROL rw
    0=Fast_slew_is_selected; 1=Slow_slew_is_selected
  [18] VOUT1_D7_INPUTENABLE rw
    0=Receive_mode_is_disabled; 1=Receive_mode_is_enabled
  [17] VOUT1_D7_PULLTYPESELECT rw
    0=Pull_Down_is_selected; 1=Pull_Up_is_selected
  [16] VOUT1_D7_PULLUDENABLE rw
    0=Enables_weak_Pull_Up/Down; 1=Disables_weak_Pull_Up/Down
  [3:0] VOUT1_D7_MUXMODE rw
    0=VOUT1_D7; 1=MCASP1_AXR7; 3=ECAP1_IN_PWM1_OUT; 4=MCASP1_AXR13; 6=EMU3; 9=VIN2A_FLD0; 14=GPIO3_0; 15=DRIVER_OFF
0x150C CTRL_CORE_PAD_VOUT1_D8 reset 0x4000F
  [19] VOUT1_D8_SLEWCONTROL rw
    0=Fast_slew_is_selected; 1=Slow_slew_is_selected
  [18] VOUT1_D8_INPUTENABLE rw
    0=Receive_mode_is_disabled; 1=Receive_mode_is_enabled
  [17] VOUT1_D8_PULLTYPESELECT rw
    0=Pull_Down_is_selected; 1=Pull_Up_is_selected
  [16] VOUT1_D8_PULLUDENABLE rw
    0=Enables_weak_Pull_Up/Down; 1=Disables_weak_Pull_Up/Down
  [3:0] VOUT1_D8_MUXMODE rw
    0=VOUT1_D8; 1=MCASP1_AXR8; 2=VIN2A_D0; 3=GPMC_A20; 6=EMU4; 14=GPIO3_1; 15=DRIVER_OFF
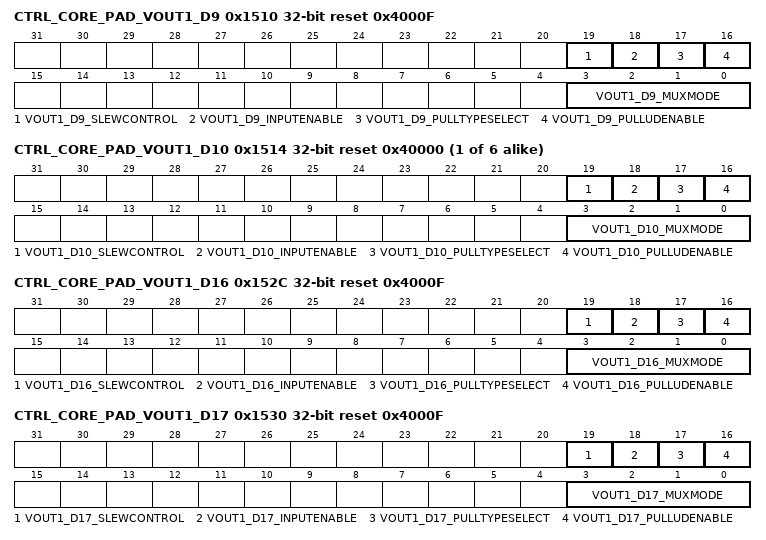
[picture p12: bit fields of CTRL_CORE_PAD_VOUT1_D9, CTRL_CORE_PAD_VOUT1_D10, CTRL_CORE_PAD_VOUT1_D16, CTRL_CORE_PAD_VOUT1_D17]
0x1510 CTRL_CORE_PAD_VOUT1_D9 reset 0x4000F
  [19] VOUT1_D9_SLEWCONTROL rw
    0=Fast_slew_is_selected; 1=Slow_slew_is_selected
  [18] VOUT1_D9_INPUTENABLE rw
    0=Receive_mode_is_disabled; 1=Receive_mode_is_enabled
  [17] VOUT1_D9_PULLTYPESELECT rw
    0=Pull_Down_is_selected; 1=Pull_Up_is_selected
  [16] VOUT1_D9_PULLUDENABLE rw
    0=Enables_weak_Pull_Up/Down; 1=Disables_weak_Pull_Up/Down
  [3:0] VOUT1_D9_MUXMODE rw
    0=VOUT1_D9; 1=MCASP1_AXR9; 2=VIN2A_D1; 3=GPMC_A21; 6=EMU5; 14=GPIO3_2; 15=DRIVER_OFF
{0x14EC+4i} CTRL_CORE_PAD_VOUT1_D{i} reset 0x40000 (reset mask 0xFFFFFFF0) (i=10..15)
  [19] VOUT1_D{i}_SLEWCONTROL rw
    0=Fast_slew_is_selected; 1=Slow_slew_is_selected
  [18] VOUT1_D{i}_INPUTENABLE rw
    0=Receive_mode_is_disabled; 1=Receive_mode_is_enabled
  [17] VOUT1_D{i}_PULLTYPESELECT rw
    0=Pull_Down_is_selected; 1=Pull_Up_is_selected
  [16] VOUT1_D{i}_PULLUDENABLE rw
    0=Enables_weak_Pull_Up/Down; 1=Disables_weak_Pull_Up/Down
  [3:0] VOUT1_D{i}_MUXMODE rw
    0=VOUT1_D{i}; 1=MCASP1_AXR{i}; 2=VIN2A_D{i-8}; 3=GPMC_A{i+12}; 6=EMU{i-4}; 14=GPIO3_{i-7}; 15=DRIVER_OFF
0x152C CTRL_CORE_PAD_VOUT1_D16 reset 0x4000F
  [19] VOUT1_D16_SLEWCONTROL rw
    0=Fast_slew_is_selected; 1=Slow_slew_is_selected
  [18] VOUT1_D16_INPUTENABLE rw
    0=Receive_mode_is_disabled; 1=Receive_mode_is_enabled
  [17] VOUT1_D16_PULLTYPESELECT rw
    0=Pull_Down_is_selected; 1=Pull_Up_is_selected
  [16] VOUT1_D16_PULLUDENABLE rw
    0=Enables_weak_Pull_Up/Down; 1=Disables_weak_Pull_Up/Down
  [3:0] VOUT1_D16_MUXMODE rw
    0=VOUT1_D16; 1=MCASP1_AHCLKX; 2=VIN2A_D8; 3=GPMC_A0; 4=MCASP1_AXR8; 5=VIN2B_D0; 6=EMU12; 14=GPIO3_9; 15=DRIVER_OFF
0x1530 CTRL_CORE_PAD_VOUT1_D17 reset 0x4000F
  [19] VOUT1_D17_SLEWCONTROL rw
    0=Fast_slew_is_selected; 1=Slow_slew_is_selected
  [18] VOUT1_D17_INPUTENABLE rw
    0=Receive_mode_is_disabled; 1=Receive_mode_is_enabled
  [17] VOUT1_D17_PULLTYPESELECT rw
    0=Pull_Down_is_selected; 1=Pull_Up_is_selected
  [16] VOUT1_D17_PULLUDENABLE rw
    0=Enables_weak_Pull_Up/Down; 1=Disables_weak_Pull_Up/Down
  [3:0] VOUT1_D17_MUXMODE rw
    0=VOUT1_D17; 2=VIN2A_D9; 3=GPMC_A1; 4=MCASP1_AXR9; 5=VIN2B_D1; 6=EMU13; 14=GPIO3_10; 15=DRIVER_OFF
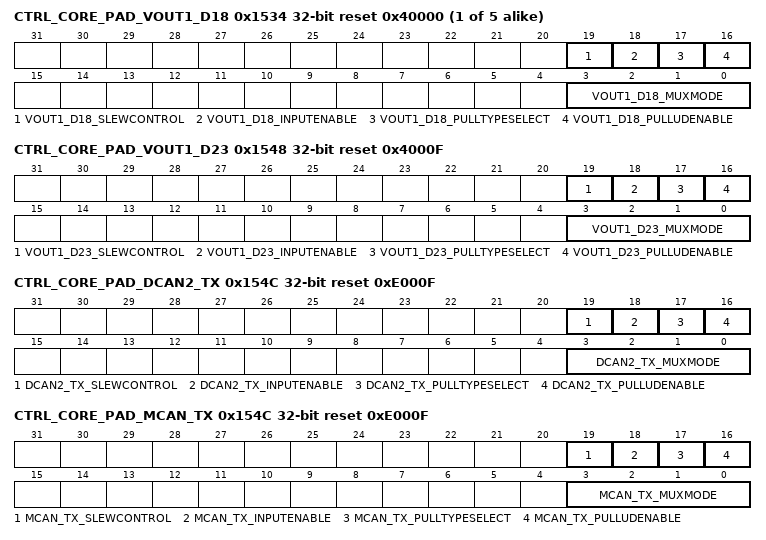
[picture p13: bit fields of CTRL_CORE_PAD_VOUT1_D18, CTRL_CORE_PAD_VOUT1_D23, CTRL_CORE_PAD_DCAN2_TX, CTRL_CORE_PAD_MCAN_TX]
{0x14EC+4i} CTRL_CORE_PAD_VOUT1_D{i} reset 0x40000 (reset mask 0xFFFFFFF0) (i=18..22)
  [19] VOUT1_D{i}_SLEWCONTROL rw
    0=Fast_slew_is_selected; 1=Slow_slew_is_selected
  [18] VOUT1_D{i}_INPUTENABLE rw
    0=Receive_mode_is_disabled; 1=Receive_mode_is_enabled
  [17] VOUT1_D{i}_PULLTYPESELECT rw
    0=Pull_Down_is_selected; 1=Pull_Up_is_selected
  [16] VOUT1_D{i}_PULLUDENABLE rw
    0=Enables_weak_Pull_Up/Down; 1=Disables_weak_Pull_Up/Down
  [3:0] VOUT1_D{i}_MUXMODE rw
    0=VOUT1_D{i}; 2=VIN2A_D{i-8}; 3=GPMC_A{i-16}; 4=MCASP1_AXR{i-8}; 5=VIN2B_D{i-16}; 6=EMU{i-4}; 14=GPIO3_{i-7}; 15=DRIVER_OFF
0x1548 CTRL_CORE_PAD_VOUT1_D23 reset 0x4000F
  [19] VOUT1_D23_SLEWCONTROL rw
    0=Fast_slew_is_selected; 1=Slow_slew_is_selected
  [18] VOUT1_D23_INPUTENABLE rw
    0=Receive_mode_is_disabled; 1=Receive_mode_is_enabled
  [17] VOUT1_D23_PULLTYPESELECT rw
    0=Pull_Down_is_selected; 1=Pull_Up_is_selected
  [16] VOUT1_D23_PULLUDENABLE rw
    0=Enables_weak_Pull_Up/Down; 1=Disables_weak_Pull_Up/Down
  [3:0] VOUT1_D23_MUXMODE rw
    0=VOUT1_D23; 2=VIN2A_D15; 3=GPMC_A7; 4=MCASP1_AXR15; 5=VIN2B_D7; 6=EMU19; 14=GPIO3_16; 15=DRIVER_OFF
0x154C CTRL_CORE_PAD_DCAN2_TX reset 0xE000F — SR1.0 Only
  [19] DCAN2_TX_SLEWCONTROL rw
    0=Fast_slew_is_selected; 1=Slow_slew_is_selected
  [18] DCAN2_TX_INPUTENABLE rw
    0=Receive_mode_is_disabled; 1=Receive_mode_is_enabled
  [17] DCAN2_TX_PULLTYPESELECT rw
    0=Pull_Down_is_selected; 1=Pull_Up_is_selected
  [16] DCAN2_TX_PULLUDENABLE rw
    0=Enables_weak_Pull_Up/Down; 1=Disables_weak_Pull_Up/Down
  [3:0] DCAN2_TX_MUXMODE rw
    0=DCAN2_TX; 1=VIN2A_DE0; 2=VIN2A_HSYNC0; 3=SPI1_CS2; 4=UART3_RXD; 5=QSPI1_CS1; 6=GPMC_WAIT1; 7=VIN1B_HSYNC1; 8=VIN1B_DE1; 14=GPIO4_11; 15=DRIVER_OFF
0x154C CTRL_CORE_PAD_MCAN_TX reset 0xE000F — SR2.0 Only
  [19] MCAN_TX_SLEWCONTROL rw
    0=Fast_slew_is_selected; 1=Slow_slew_is_selected
  [18] MCAN_TX_INPUTENABLE rw
    0=Receive_mode_is_disabled; 1=Receive_mode_is_enabled
  [17] MCAN_TX_PULLTYPESELECT rw
    0=Pull_Down_is_selected; 1=Pull_Up_is_selected
  [16] MCAN_TX_PULLUDENABLE rw
    0=Enables_weak_Pull_Up/Down; 1=Disables_weak_Pull_Up/Down
  [3:0] MCAN_TX_MUXMODE rw
    0=MCAN_TX; 1=VIN2A_DE0; 2=VIN2A_HSYNC0; 3=SPI1_CS2; 4=UART3_RXD; 5=QSPI1_CS1; 6=GPMC_WAIT1; 7=VIN1B_HSYNC1; 8=VIN1B_DE1; 14=GPIO4_11; 15=DRIVER_OFF
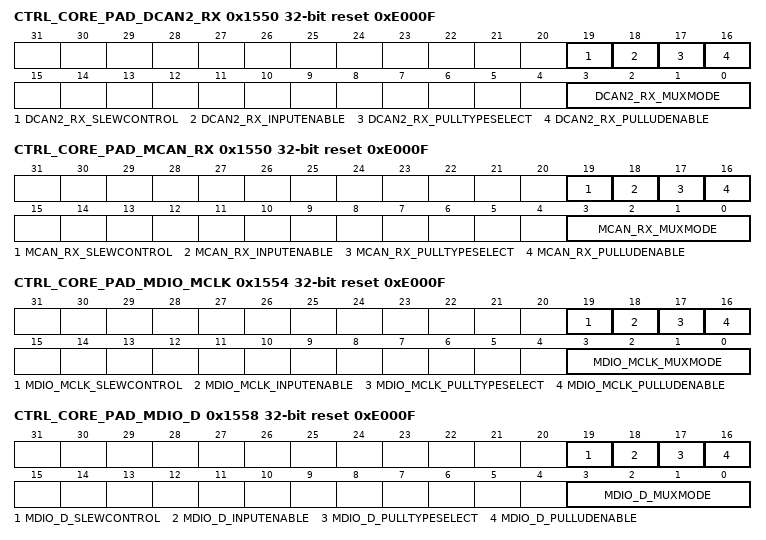
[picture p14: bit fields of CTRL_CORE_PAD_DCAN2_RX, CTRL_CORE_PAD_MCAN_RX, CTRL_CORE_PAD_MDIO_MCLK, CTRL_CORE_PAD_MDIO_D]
0x1550 CTRL_CORE_PAD_DCAN2_RX reset 0xE000F — SR1.0 Only
  [19] DCAN2_RX_SLEWCONTROL rw
    0=Fast_slew_is_selected; 1=Slow_slew_is_selected
  [18] DCAN2_RX_INPUTENABLE rw
    0=Receive_mode_is_disabled; 1=Receive_mode_is_enabled
  [17] DCAN2_RX_PULLTYPESELECT rw
    0=Pull_Down_is_selected; 1=Pull_Up_is_selected
  [16] DCAN2_RX_PULLUDENABLE rw
    0=Enables_weak_Pull_Up/Down; 1=Disables_weak_Pull_Up/Down
  [3:0] DCAN2_RX_MUXMODE rw
    0=DCAN2_RX; 1=CAM_NRESET; 2=VIN2A_VSYNC0; 3=SPI1_CS3; 4=UART3_TXD; 5=GPMC_CS7; 7=VIN1B_VSYNC1; 14=GPIO4_12; 15=DRIVER_OFF
0x1550 CTRL_CORE_PAD_MCAN_RX reset 0xE000F — SR2.0 Only
  [19] MCAN_RX_SLEWCONTROL rw
    0=Fast_slew_is_selected; 1=Slow_slew_is_selected
  [18] MCAN_RX_INPUTENABLE rw
    0=Receive_mode_is_disabled; 1=Receive_mode_is_enabled
  [17] MCAN_RX_PULLTYPESELECT rw
    0=Pull_Down_is_selected; 1=Pull_Up_is_selected
  [16] MCAN_RX_PULLUDENABLE rw
    0=Enables_weak_Pull_Up/Down; 1=Disables_weak_Pull_Up/Down
  [3:0] MCAN_RX_MUXMODE rw
    0=MCAN_RX; 1=CAM_NRESET; 2=VIN2A_VSYNC0; 3=SPI1_CS3; 4=UART3_TXD; 5=GPMC_CS7; 7=VIN1B_VSYNC1; 14=GPIO4_12; 15=DRIVER_OFF
0x1554 CTRL_CORE_PAD_MDIO_MCLK reset 0xE000F
  [19] MDIO_MCLK_SLEWCONTROL rw
    0=Fast_slew_is_selected; 1=Slow_slew_is_selected
  [18] MDIO_MCLK_INPUTENABLE rw
    0=Receive_mode_is_disabled; 1=Receive_mode_is_enabled
  [17] MDIO_MCLK_PULLTYPESELECT rw
    0=Pull_Down_is_selected; 1=Pull_Up_is_selected
  [16] MDIO_MCLK_PULLUDENABLE rw
    0=Enables_weak_Pull_Up/Down; 1=Disables_weak_Pull_Up/Down
  [3:0] MDIO_MCLK_MUXMODE rw
    0=MDIO_MCLK; 4=SPI4_D1; 14=GPIO3_17; 15=DRIVER_OFF
0x1558 CTRL_CORE_PAD_MDIO_D reset 0xE000F
  [19] MDIO_D_SLEWCONTROL rw
    0=Fast_slew_is_selected; 1=Slow_slew_is_selected
  [18] MDIO_D_INPUTENABLE rw
    0=Receive_mode_is_disabled; 1=Receive_mode_is_enabled
  [17] MDIO_D_PULLTYPESELECT rw
    0=Pull_Down_is_selected; 1=Pull_Up_is_selected
  [16] MDIO_D_PULLUDENABLE rw
    0=Enables_weak_Pull_Up/Down; 1=Disables_weak_Pull_Up/Down
  [3:0] MDIO_D_MUXMODE rw
    0=MDIO_D; 4=SPI4_D0; 5=ESM_ERROR; 14=GPIO3_18; 15=DRIVER_OFF
0x155C CTRL_CORE_PAD_RGMII0_TXC reset 0x4000F
  [19] RGMII0_TXC_SLEWCONTROL rw
    0=Fast_slew_is_selected; 1=Slow_slew_is_selected
  [18] RGMII0_TXC_INPUTENABLE rw
    0=Receive_mode_is_disabled; 1=Receive_mode_is_enabled
  [17] RGMII0_TXC_PULLTYPESELECT rw
    0=Pull_Down_is_selected; 1=Pull_Up_is_selected
  [16] RGMII0_TXC_PULLUDENABLE rw
    0=Enables_weak_Pull_Up/Down; 1=Disables_weak_Pull_Up/Down
  [3:0] RGMII0_TXC_MUXMODE rw
    0=RGMII0_TXC; 3=CAM_STROBE; 4=SPI4_SCLK; 5=MMC_CLK; 14=GPIO3_19; 15=DRIVER_OFF
0x1560 CTRL_CORE_PAD_RGMII0_TXCTL reset 0x4000F
  [19] RGMII0_TXCTL_SLEWCONTROL rw
    0=Fast_slew_is_selected; 1=Slow_slew_is_selected
  [18] RGMII0_TXCTL_INPUTENABLE rw
    0=Receive_mode_is_disabled; 1=Receive_mode_is_enabled
  [17] RGMII0_TXCTL_PULLTYPESELECT rw
    0=Pull_Down_is_selected; 1=Pull_Up_is_selected
  [16] RGMII0_TXCTL_PULLUDENABLE rw
    0=Enables_weak_Pull_Up/Down; 1=Disables_weak_Pull_Up/Down
  [3:0] RGMII0_TXCTL_MUXMODE rw
    0=RGMII0_TXCTL; 3=CAM_SHUTTER; 4=SPI4_CS0; 5=MMC_CMD; 14=GPIO3_20; 15=DRIVER_OFF
0x1564 CTRL_CORE_PAD_RGMII0_TXD3 reset 0x4000F
  [19] RGMII0_TXD3_SLEWCONTROL rw
    0=Fast_slew_is_selected; 1=Slow_slew_is_selected
  [18] RGMII0_TXD3_INPUTENABLE rw
    0=Receive_mode_is_disabled; 1=Receive_mode_is_enabled
  [17] RGMII0_TXD3_PULLTYPESELECT rw
    0=Pull_Down_is_selected; 1=Pull_Up_is_selected
  [16] RGMII0_TXD3_PULLUDENABLE rw
    0=Enables_weak_Pull_Up/Down; 1=Disables_weak_Pull_Up/Down
  [3:0] RGMII0_TXD3_MUXMODE rw
    0=RGMII0_TXD3; 5=MMC_DAT0; 14=GPIO3_21; 15=DRIVER_OFF
0x1568 CTRL_CORE_PAD_RGMII0_TXD2 reset 0x4000F
  [19] RGMII0_TXD2_SLEWCONTROL rw
    0=Fast_slew_is_selected; 1=Slow_slew_is_selected
  [18] RGMII0_TXD2_INPUTENABLE rw
    0=Receive_mode_is_disabled; 1=Receive_mode_is_enabled
  [17] RGMII0_TXD2_PULLTYPESELECT rw
    0=Pull_Down_is_selected; 1=Pull_Up_is_selected
  [16] RGMII0_TXD2_PULLUDENABLE rw
    0=Enables_weak_Pull_Up/Down; 1=Disables_weak_Pull_Up/Down
  [3:0] RGMII0_TXD2_MUXMODE rw
    0=RGMII0_TXD2; 3=ECAP1_IN_PWM1_OUT; 5=MMC_DAT1; 14=GPIO3_22; 15=DRIVER_OFF
0x156C CTRL_CORE_PAD_RGMII0_TXD1 reset 0x4000F
  [19] RGMII0_TXD1_SLEWCONTROL rw
    0=Fast_slew_is_selected; 1=Slow_slew_is_selected
  [18] RGMII0_TXD1_INPUTENABLE rw
    0=Receive_mode_is_disabled; 1=Receive_mode_is_enabled
  [17] RGMII0_TXD1_PULLTYPESELECT rw
    0=Pull_Down_is_selected; 1=Pull_Up_is_selected
  [16] RGMII0_TXD1_PULLUDENABLE rw
    0=Enables_weak_Pull_Up/Down; 1=Disables_weak_Pull_Up/Down
  [3:0] RGMII0_TXD1_MUXMODE rw
    0=RGMII0_TXD1; 5=MMC_DAT2; 14=GPIO3_23; 15=DRIVER_OFF
0x1570 CTRL_CORE_PAD_RGMII0_TXD0 reset 0x4000F
  [19] RGMII0_TXD0_SLEWCONTROL rw
    0=Fast_slew_is_selected; 1=Slow_slew_is_selected
  [18] RGMII0_TXD0_INPUTENABLE rw
    0=Receive_mode_is_disabled; 1=Receive_mode_is_enabled
  [17] RGMII0_TXD0_PULLTYPESELECT rw
    0=Pull_Down_is_selected; 1=Pull_Up_is_selected
  [16] RGMII0_TXD0_PULLUDENABLE rw
    0=Enables_weak_Pull_Up/Down; 1=Disables_weak_Pull_Up/Down
  [3:0] RGMII0_TXD0_MUXMODE rw
    0=RGMII0_TXD0; 5=MMC_DAT3; 14=GPIO3_24; 15=DRIVER_OFF
0x1574 CTRL_CORE_PAD_RGMII0_RXC reset 0x4000F
  [19] RGMII0_RXC_SLEWCONTROL rw
    0=Fast_slew_is_selected; 1=Slow_slew_is_selected
  [18] RGMII0_RXC_INPUTENABLE rw
    0=Receive_mode_is_disabled; 1=Receive_mode_is_enabled
  [17] RGMII0_RXC_PULLTYPESELECT rw
    0=Pull_Down_is_selected; 1=Pull_Up_is_selected
  [16] RGMII0_RXC_PULLUDENABLE rw
    0=Enables_weak_Pull_Up/Down; 1=Disables_weak_Pull_Up/Down
  [3:0] RGMII0_RXC_MUXMODE rw
    0=RGMII0_RXC; 3=CAM_STROBE; 5=MMC_CLK; 14=GPIO3_25; 15=DRIVER_OFF
0x1578 CTRL_CORE_PAD_RGMII0_RXCTL reset 0x4000F
  [19] RGMII0_RXCTL_SLEWCONTROL rw
    0=Fast_slew_is_selected; 1=Slow_slew_is_selected
  [18] RGMII0_RXCTL_INPUTENABLE rw
    0=Receive_mode_is_disabled; 1=Receive_mode_is_enabled
  [17] RGMII0_RXCTL_PULLTYPESELECT rw
    0=Pull_Down_is_selected; 1=Pull_Up_is_selected
  [16] RGMII0_RXCTL_PULLUDENABLE rw
    0=Enables_weak_Pull_Up/Down; 1=Disables_weak_Pull_Up/Down
  [3:0] RGMII0_RXCTL_MUXMODE rw
    0=RGMII0_RXCTL; 3=CAM_SHUTTER; 5=MMC_CMD; 14=GPIO3_26; 15=DRIVER_OFF
0x157C CTRL_CORE_PAD_RGMII0_RXD3 reset 0x4000F
  [19] RGMII0_RXD3_SLEWCONTROL rw
    0=Fast_slew_is_selected; 1=Slow_slew_is_selected
  [18] RGMII0_RXD3_INPUTENABLE rw
    0=Receive_mode_is_disabled; 1=Receive_mode_is_enabled
  [17] RGMII0_RXD3_PULLTYPESELECT rw
    0=Pull_Down_is_selected; 1=Pull_Up_is_selected
  [16] RGMII0_RXD3_PULLUDENABLE rw
    0=Enables_weak_Pull_Up/Down; 1=Disables_weak_Pull_Up/Down
  [3:0] RGMII0_RXD3_MUXMODE rw
    0=RGMII0_RXD3; 5=MMC_DAT0; 14=GPIO3_27; 15=DRIVER_OFF
0x1580 CTRL_CORE_PAD_RGMII0_RXD2 reset 0x4000F
  [19] RGMII0_RXD2_SLEWCONTROL rw
    0=Fast_slew_is_selected; 1=Slow_slew_is_selected
  [18] RGMII0_RXD2_INPUTENABLE rw
    0=Receive_mode_is_disabled; 1=Receive_mode_is_enabled
  [17] RGMII0_RXD2_PULLTYPESELECT rw
    0=Pull_Down_is_selected; 1=Pull_Up_is_selected
  [16] RGMII0_RXD2_PULLUDENABLE rw
    0=Enables_weak_Pull_Up/Down; 1=Disables_weak_Pull_Up/Down
  [3:0] RGMII0_RXD2_MUXMODE rw
    0=RGMII0_RXD2; 5=MMC_DAT1; 14=GPIO3_28; 15=DRIVER_OFF
0x1584 CTRL_CORE_PAD_RGMII0_RXD1 reset 0x4000F
  [19] RGMII0_RXD1_SLEWCONTROL rw
    0=Fast_slew_is_selected; 1=Slow_slew_is_selected
  [18] RGMII0_RXD1_INPUTENABLE rw
    0=Receive_mode_is_disabled; 1=Receive_mode_is_enabled
  [17] RGMII0_RXD1_PULLTYPESELECT rw
    0=Pull_Down_is_selected; 1=Pull_Up_is_selected
  [16] RGMII0_RXD1_PULLUDENABLE rw
    0=Enables_weak_Pull_Up/Down; 1=Disables_weak_Pull_Up/Down
  [3:0] RGMII0_RXD1_MUXMODE rw
    0=RGMII0_RXD1; 5=MMC_DAT2; 14=GPIO3_29; 15=DRIVER_OFF
0x1588 CTRL_CORE_PAD_RGMII0_RXD0 reset 0x4000F
  [19] RGMII0_RXD0_SLEWCONTROL rw
    0=Fast_slew_is_selected; 1=Slow_slew_is_selected
  [18] RGMII0_RXD0_INPUTENABLE rw
    0=Receive_mode_is_disabled; 1=Receive_mode_is_enabled
  [17] RGMII0_RXD0_PULLTYPESELECT rw
    0=Pull_Down_is_selected; 1=Pull_Up_is_selected
  [16] RGMII0_RXD0_PULLUDENABLE rw
    0=Enables_weak_Pull_Up/Down; 1=Disables_weak_Pull_Up/Down
  [3:0] RGMII0_RXD0_MUXMODE rw
    0=RGMII0_RXD0; 5=MMC_DAT3; 14=GPIO3_30; 15=DRIVER_OFF
0x158C CTRL_CORE_PAD_XREF_CLK0 reset 0x4000F
  [19] XREF_CLK0_SLEWCONTROL rw
    0=Fast_slew_is_selected; 1=Slow_slew_is_selected
  [18] XREF_CLK0_INPUTENABLE rw
    0=Receive_mode_is_disabled; 1=Receive_mode_is_enabled
  [17] XREF_CLK0_PULLTYPESELECT rw
    0=Pull_Down_is_selected; 1=Pull_Up_is_selected
  [16] XREF_CLK0_PULLUDENABLE rw
    0=Enables_weak_Pull_Up/Down; 1=Disables_weak_Pull_Up/Down
  [3:0] XREF_CLK0_MUXMODE rw
    0=XREF_CLK0; 1=CLKOUT0; 4=SPI3_CS0; 5=SPI2_CS1; 6=SPI1_CS0; 7=SPI1_CS1; 14=GPIO3_31; 15=DRIVER_OFF
